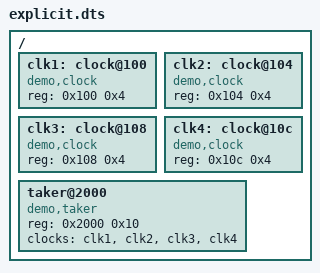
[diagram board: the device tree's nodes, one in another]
/dts-v1/;

/ {
	#address-cells = <1>;
	#size-cells = <1>;

	clk1: clock@100 {
		compatible = "demo,clock";
		reg = <0x100 0x4>;
		#clock-cells = <0>;
		phandle = <0x21>;
	};

	clk2: clock@104 {
		compatible = "demo,clock";
		reg = <0x104 0x4>;
		#clock-cells = <0>;
	};

	clk3: clock@108 {
		compatible = "demo,clock";
		reg = <0x108 0x4>;
		#clock-cells = <0>;
		phandle = <0x1>;
	};

	clk4: clock@10c {
		compatible = "demo,clock";
		reg = <0x10c 0x4>;
		#clock-cells = <0>;
	};

	taker@2000 {
		compatible = "demo,taker";
		reg = <0x2000 0x10>;
		clocks = <&clk1>, <&clk2>, <&clk3>, <&clk4>;
	};
};
